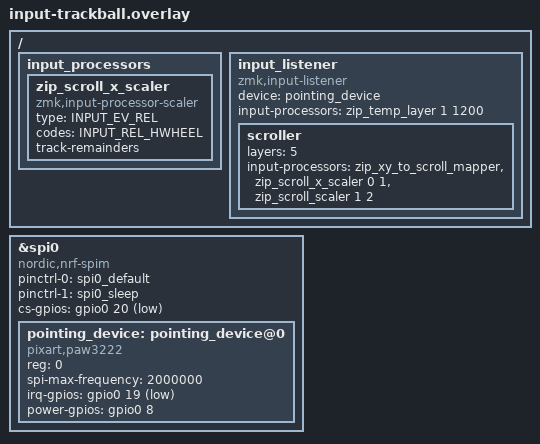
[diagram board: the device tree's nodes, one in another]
#include <zephyr/dt-bindings/input/input-event-codes.h>

&spi0 {
    status = "okay";
    compatible = "nordic,nrf-spim";
    pinctrl-0 = <&spi0_default>;
    pinctrl-1 = <&spi0_sleep>;
    pinctrl-names = "default", "sleep";
    cs-gpios = <&gpio0 20 GPIO_ACTIVE_LOW>;

    pointing_device: pointing_device@0 {
        status = "okay";
        compatible = "pixart,paw3222";
        reg = <0>;
        spi-max-frequency = <2000000>;
        irq-gpios = <&gpio0 19 GPIO_ACTIVE_LOW>;
        power-gpios = <&gpio0 8 (GPIO_ACTIVE_HIGH | NRF_GPIO_DRIVE_H0H1)>;
    };
};

/ {
    input_processors {
        zip_scroll_x_scaler: zip_scroll_x_scaler {
            compatible = "zmk,input-processor-scaler";
            #input-processor-cells = <2>;
            type = <INPUT_EV_REL>;
            codes = <INPUT_REL_HWHEEL>;
            track-remainders;
        };
    };
};

/ {
    input_listener {
        compatible = "zmk,input-listener";
        device = <&pointing_device>;
        /* Auto mouse */
        input-processors = <&zip_temp_layer 1 1200>;

        scroller {
            layers = <5>;
            input-processors = <
                &zip_xy_to_scroll_mapper
                &zip_scroll_x_scaler 0 1
                &zip_scroll_scaler 1 2 // Scroll sensitivity setting (making the denominator larger slows it down)
            >;
        };
    };
};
